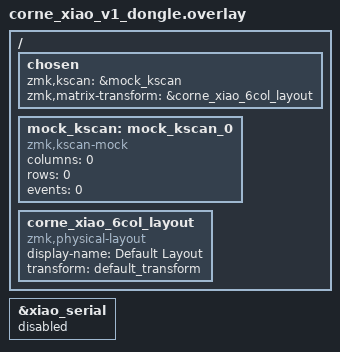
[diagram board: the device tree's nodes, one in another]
#include <dt-bindings/zmk/matrix_transform.h>
#include <layouts/corne_xiao/6column.dtsi>

&xiao_serial { status = "disabled"; };

&corne_xiao_6col_layout {
    transform = <&default_transform>;
};

/ {
    chosen {
      zmk,kscan = &mock_kscan;
      zmk,matrix-transform = &corne_xiao_6col_layout;
    };


    mock_kscan: mock_kscan_0 {
        compatible = "zmk,kscan-mock";
        columns = <0>;
        rows = <0>;
        events = <0>;
    };

    corne_xiao_6col_layout: corne_xiao_6col_layout {
        compatible = "zmk,physical-layout";
        display-name = "Default Layout";
        transform = <&default_transform>;
    };
};
